AUTOSAR XML (schema 00049)
standard types defined: boolean, float32, sint16, uint8, boolean_CompuMethod, boolean_DataConstr, float32_DataConstr, sint16_DataConstr, uint8_DataConstr
package /ComponentTypes
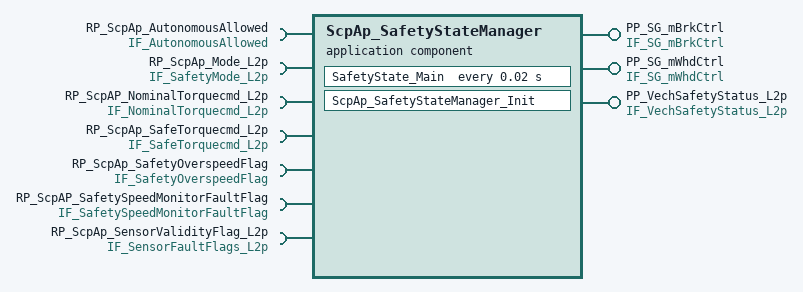
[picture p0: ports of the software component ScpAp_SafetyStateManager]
  application sw component type ScpAp_SafetyStateManager
    7 x require port:
      RP_ScpAp_AutonomousAllowed: nonqueued-receiver-com-spec{data-element=IF_AutonomousAllowed, init-value=0}, required-interface=IF_AutonomousAllowed
      RP_ScpAp_Mode_L2p: nonqueued-receiver-com-spec{data-element=IF_SafetyMode_L2p, init-value=AUTONOMOUS}, required-interface=IF_SafetyMode_L2p
      RP_ScpAP_NominalTorquecmd_L2p: nonqueued-receiver-com-spec{data-element=IF_NominalTorquecmd_L2p, init-value=0}, required-interface=IF_NominalTorquecmd_L2p
      RP_ScpAp_SafeTorquecmd_L2p: nonqueued-receiver-com-spec{data-element=IF_SafeTorquecmd_L2p, init-value=0}, required-interface=IF_SafeTorquecmd_L2p
      RP_ScpAp_SafetyOverspeedFlag: nonqueued-receiver-com-spec{data-element=IF_SafetyOverspeedFlag, init-value=ComSpec6968f42a_68ad0311d0d789b3:0}, required-interface=IF_SafetyOverspeedFlag
      RP_ScpAP_SafetySpeedMonitorFaultFlag: nonqueued-receiver-com-spec{data-element=IF_SafetySpeedMonitorFaultFlag, init-value=ComSpecf84f6e99_1a9cf03014e21de2:0}, required-interface=IF_SafetySpeedMonitorFaultFlag
      RP_ScpAp_SensorValidityFlag_L2p: nonqueued-receiver-com-spec{data-element=IF_SensorFaultFlags_L2p, init-value={short-label=ComSpec84119ff2_2545e808b3362872, fields=[MotorRPM_Fault:0, Accel_Fault:0, WSS_Fault:0, VechSpeedEst_Fault:0]}}, required-interface=IF_SensorFaultFlags_L2p
    provide port PP_SG_mBrkCtrl: nonqueued-sender-com-spec{data-element=SG_mBrkCtrl_VDP, init-value={short-label=ComSpec3ce80adb_42ffe0d9d679ecb2, fields=[Aeb_Active_Ebcm:0, BrkEnbl_EBCM2L:0, BrkTrqRq:0, ClearFltRq_Ebcm:0, DsblTCS:0, EbcmMaintModeRq:0, EbcmShtdwnRq:0, EpbCalCmd:0, EPBCmd:0, HoldRq:0, MsgCntr_mBrkCtrl:0, MsgCrc_mBrkCtrl:0]}}, provided-interface=IF_SG_mBrkCtrl
    provide port PP_SG_mWhdCtrl: nonqueued-sender-com-spec{data-element=SG_mWhdCtrl_VDP, init-value={short-label=ComSpec52014817_cbff72f33b0d015a, fields=[Boot:0, CtrlMode_Whd:0, Debug:0, EnblCmd:0, MsgCntr_mWhdCtrl:0, MsgCrc_mWhdCtrl:0, MtrMode:0, SpdCmd:0, SpdSlewLmt:0, TrqCmd:0, TrqSlewLmt:0]}}, provided-interface=IF_SG_mWhdCtrl
    provide port PP_VechSafetyStatus_L2p: nonqueued-sender-com-spec{data-element=IF_VechSafetyStatus_L2p, init-value=NORMAL}, provided-interface=IF_VechSafetyStatus_L2p
    behavior ScpAp_SafetyStateManager_InternalBehavior: handle-termination-and-restart=NO-SUPPORT
      static-memorys:
        25 x data, all with category=VALUE, sw-addr-method=ASW_Variables, sw-calibration-access=READ-ONLY:
          ScpAp_SafetyStateManag_BrkTrqRq: type=float32
          ScpAp_SafetyStateManager_TrqCmd: type=float32
          ScpAp_SafetyStateManager_SpdCmd: type=float32
          ScpAp_SafetyStateMan_SpdSlewLmt: type=float32
          ScpAp_SafetyStateMan_TrqSlewLmt: type=float32
          ScpAp_SafetyS_SafeTorquecmd_L2p: type=float32
          ScpAp_SafetySta_MsgCrc_mBrkCtrl: type=uint8
          ScpAp_SafetyStateManager_EPBCmd: type=uint8
          ScpAp_SafetySt_MsgCntr_mBrkCtrl: type=uint8
          ScpAp_SafetyStateM_CtrlMode_Whd: type=uint8
          ScpAp_SafetySt_MsgCntr_mWhdCtrl: type=uint8
          ScpAp_SafetySta_MsgCrc_mWhdCtrl: type=uint8
          ScpAp_SafetyStateManage_MtrMode: type=uint8
          ScpAp_SafetySta_Aeb_Active_Ebcm: type=boolean
          ScpAp_SafetyStat_BrkEnbl_EBCM2L: type=boolean
          ScpAp_SafetySta_ClearFltRq_Ebcm: type=boolean
          ScpAp_SafetyStateManage_DsblTCS: type=boolean
          ScpAp_SafetySta_EbcmMaintModeRq: type=boolean
          ScpAp_SafetyStateM_EbcmShtdwnRq: type=boolean
          ScpAp_SafetyStateMana_EpbCalCmd: type=boolean
          ScpAp_SafetyStateManager_HoldRq: type=boolean
          ScpAp_SafetyStateManager_Boot: type=boolean
          ScpAp_SafetyStateManager_Debug: type=boolean
          ScpAp_SafetyStateManage_EnblCmd: type=boolean
          ScpAp_SafetySta_MultiportSwitch: type=VechSafetyStatus_L2p_IDT
      timing event TMT_SafetyState_Main: start-on-event=SafetyState_Main, period=0.02
      runnable SafetyState_Main: sw-addr-method=CODE
        data-receive-point-by-arguments:
          4 x access:
            IN_RP_ScpAP_SafetySpeedMonitorFaultFlag_IF_SafetySpeedMonitorFaultFlag: accessed-variable=RP_ScpAP_SafetySpeedMonitorFaultFlag.IF_SafetySpeedMonitorFaultFlag
            IN_RP_ScpAp_SafeTorquecmd_L2p_IF_SafeTorquecmd_L2p: accessed-variable=RP_ScpAp_SafeTorquecmd_L2p.IF_SafeTorquecmd_L2p
            IN_RP_ScpAp_SafetyOverspeedFlag_IF_SafetyOverspeedFlag: accessed-variable=RP_ScpAp_SafetyOverspeedFlag.IF_SafetyOverspeedFlag
            IN_RP_ScpAp_SensorValidityFlag_L2p_IF_SensorFaultFlags_L2p: accessed-variable=RP_ScpAp_SensorValidityFlag_L2p.IF_SensorFaultFlags_L2p
        data-send-points:
          access OUT_PP_SG_mBrkCtrl_SG_mBrkCtrl_VDP: accessed-variable=PP_SG_mBrkCtrl.SG_mBrkCtrl_VDP
          access OUT_PP_SG_mWhdCtrl_SG_mWhdCtrl_VDP: accessed-variable=PP_SG_mWhdCtrl.SG_mWhdCtrl_VDP
          access OUT_PP_VechSafetyStatus_L2p_IF_VechSafetyStatus_L2p: accessed-variable=PP_VechSafetyStatus_L2p.IF_VechSafetyStatus_L2p
      runnable ScpAp_SafetyStateManager_Init: sw-addr-method=CODE
package /DataTypes
  5 x impl type:
    IF_SensorFaultFlgs_L2p_IDT: category=STRUCTURE
      4 x element, all with category=TYPE_REFERENCE, implementation-data-type=boolean:
        MotorRPM_Fault
        Accel_Fault
        WSS_Fault
        VechSpeedEst_Fault
    SG_mBrkCtrl_IDT: category=STRUCTURE
      12 x element, all with category=TYPE_REFERENCE:
        Aeb_Active_Ebcm: implementation-data-type=boolean
        BrkEnbl_EBCM2L: implementation-data-type=boolean
        BrkTrqRq: implementation-data-type=float32
        ClearFltRq_Ebcm: implementation-data-type=boolean
        DsblTCS: implementation-data-type=boolean
        EbcmMaintModeRq: implementation-data-type=boolean
        EbcmShtdwnRq: implementation-data-type=boolean
        EpbCalCmd: implementation-data-type=boolean
        EPBCmd: implementation-data-type=uint8
        HoldRq: implementation-data-type=boolean
        MsgCntr_mBrkCtrl: implementation-data-type=uint8
        MsgCrc_mBrkCtrl: implementation-data-type=uint8
    SG_mWhdCtrl_IDT: category=STRUCTURE
      11 x element, all with category=TYPE_REFERENCE:
        Boot: implementation-data-type=boolean
        CtrlMode_Whd: implementation-data-type=uint8
        Debug: implementation-data-type=boolean
        EnblCmd: implementation-data-type=boolean
        MsgCntr_mWhdCtrl: implementation-data-type=uint8
        MsgCrc_mWhdCtrl: implementation-data-type=uint8
        MtrMode: implementation-data-type=uint8
        SpdCmd: implementation-data-type=float32
        SpdSlewLmt: implementation-data-type=float32
        TrqCmd: implementation-data-type=float32
        TrqSlewLmt: implementation-data-type=float32
    SafetyMode_L2p_IDT: category=VALUE, base-type=BaseTypes/uint8, compu {1=AUTONOMOUS, 0=MANUAL, 3=TELEOPS}, data-constr=DC_SafetyMode_L2p_IDT
    VechSafetyStatus_L2p_IDT: category=VALUE, base-type=BaseTypes/uint8, compu {0=NORMAL, 1=DEGRADED, 2=FAULT_STOP, 3=OVERSPEED_HANDLING}, data-constr=DC_VechSafetyStatus_L2p_IDT
package /PortInterfaces
  10 x sender receiver interface:
    IF_AutonomousAllowed: invalidation-policy{data-element=IF_AutonomousAllowed, handle-invalid=DONT-INVALIDATE}
      data IF_AutonomousAllowed: category=VALUE, sw-calibration-access=READ-ONLY, type=boolean
    IF_NominalTorquecmd_L2p: invalidation-policy{data-element=IF_NominalTorquecmd_L2p, handle-invalid=DONT-INVALIDATE}
      data IF_NominalTorquecmd_L2p: category=VALUE, sw-calibration-access=READ-ONLY, type=sint16
    IF_SafeTorquecmd_L2p: invalidation-policy{data-element=IF_SafeTorquecmd_L2p, handle-invalid=DONT-INVALIDATE}
      data IF_SafeTorquecmd_L2p: category=VALUE, sw-calibration-access=READ-ONLY, type=sint16
    IF_SafetyMode_L2p: invalidation-policy{data-element=IF_SafetyMode_L2p, handle-invalid=DONT-INVALIDATE}
      data IF_SafetyMode_L2p: category=VALUE, sw-calibration-access=READ-ONLY, type=SafetyMode_L2p_IDT
    IF_SafetyOverspeedFlag: invalidation-policy{data-element=IF_SafetyOverspeedFlag, handle-invalid=DONT-INVALIDATE}
      data IF_SafetyOverspeedFlag: category=VALUE, sw-calibration-access=READ-ONLY, type=boolean
    IF_SafetySpeedMonitorFaultFlag: invalidation-policy{data-element=IF_SafetySpeedMonitorFaultFlag, handle-invalid=DONT-INVALIDATE}
      data IF_SafetySpeedMonitorFaultFlag: category=VALUE, sw-calibration-access=READ-ONLY, type=boolean
    IF_SensorFaultFlags_L2p: invalidation-policy{data-element=IF_SensorFaultFlags_L2p, handle-invalid=DONT-INVALIDATE}
      data IF_SensorFaultFlags_L2p: category=STRUCTURE, sw-calibration-access=READ-ONLY, type=IF_SensorFaultFlgs_L2p_IDT
    IF_SG_mBrkCtrl: invalidation-policy{data-element=SG_mBrkCtrl_VDP, handle-invalid=DONT-INVALIDATE}
      data SG_mBrkCtrl_VDP: category=STRUCTURE, sw-calibration-access=READ-ONLY, type=SG_mBrkCtrl_IDT
    IF_SG_mWhdCtrl: invalidation-policy{data-element=SG_mWhdCtrl_VDP, handle-invalid=DONT-INVALIDATE}
      data SG_mWhdCtrl_VDP: category=STRUCTURE, sw-calibration-access=READ-ONLY, type=SG_mWhdCtrl_IDT
    IF_VechSafetyStatus_L2p: invalidation-policy{data-element=IF_VechSafetyStatus_L2p, handle-invalid=DONT-INVALIDATE}
      data IF_VechSafetyStatus_L2p: category=VALUE, sw-calibration-access=READ-ONLY, type=VechSafetyStatus_L2p_IDT
